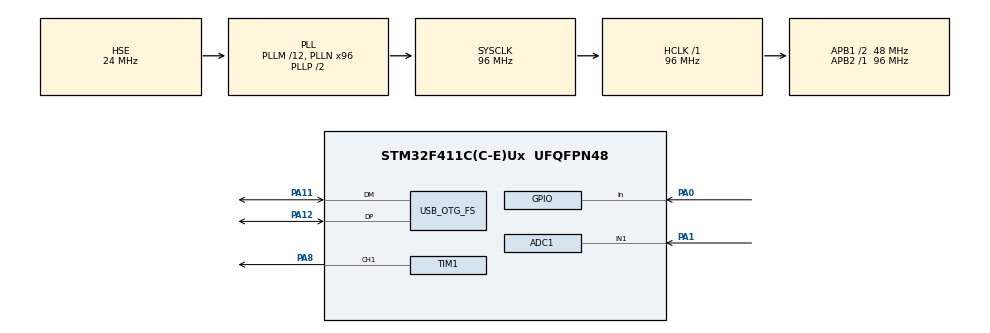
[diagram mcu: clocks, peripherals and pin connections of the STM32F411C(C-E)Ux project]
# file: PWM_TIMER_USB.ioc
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ADC1.Channel-0\#ChannelRegularConversion=ADC_CHANNEL_1
ADC1.NbrOfConversionFlag=1
ADC1.Rank-0\#ChannelRegularConversion=1
ADC1.SamplingTime-0\#ChannelRegularConversion=ADC_SAMPLETIME_3CYCLES
ADC1.master=1
Mcu.Family=STM32F4
Mcu.Name=STM32F411C(C-E)Ux
Mcu.Package=UFQFPN48
NVIC.ADC_IRQn=true\:0\:0\:false\:false\:true\:true\:true\:true
NVIC.OTG_FS_IRQn=true\:0\:0\:false\:false\:true\:false\:true\:true
NVIC.PriorityGroup=NVIC_PRIORITYGROUP_4
PA0-WKUP.GPIO_PuPd=GPIO_PULLUP
PA0-WKUP.Signal=GPIO_Input
PA1.Signal=ADCx_IN1
PA11.Mode=Device_Only
PA11.Signal=USB_OTG_FS_DM
PA12.Mode=Device_Only
PA12.Signal=USB_OTG_FS_DP
PA13.Mode=Serial_Wire
PA13.Signal=SYS_JTMS-SWDIO
PA14.Mode=Serial_Wire
PA14.Signal=SYS_JTCK-SWCLK
PA8.GPIO_PuPd=GPIO_NOPULL
PA8.Signal=S_TIM1_CH1
PH0\ -\ OSC_IN.Mode=HSE-External-Oscillator
PH0\ -\ OSC_IN.Signal=RCC_OSC_IN
PH1\ -\ OSC_OUT.Mode=HSE-External-Oscillator
PH1\ -\ OSC_OUT.Signal=RCC_OSC_OUT
ProjectManager.HeapSize=0x200
ProjectManager.StackSize=0x400
ProjectManager.TargetToolchain=STM32CubeIDE
RCC.48MHZClocksFreq_Value=48000000
RCC.AHBFreq_Value=96000000
RCC.APB1CLKDivider=RCC_HCLK_DIV2
RCC.APB1Freq_Value=48000000
RCC.APB1TimFreq_Value=96000000
RCC.APB2Freq_Value=96000000
RCC.APB2TimFreq_Value=96000000
RCC.CortexFreq_Value=96000000
RCC.HCLKFreq_Value=96000000
RCC.HSE_VALUE=24000000
RCC.HSI_VALUE=16000000
RCC.LSE_VALUE=32768
RCC.PLLM=12
RCC.PLLN=96
RCC.SYSCLKFreq_VALUE=96000000
RCC.SYSCLKSource=RCC_SYSCLKSOURCE_PLLCLK
RCC.VCOOutputFreq_Value=192000000
SH.ADCx_IN1.0=ADC1_IN1,IN1
SH.S_TIM1_CH1.0=TIM1_CH1,PWM Generation1 CH1
TIM1.AutoReloadPreload=TIM_AUTORELOAD_PRELOAD_DISABLE
TIM1.Channel-PWM\ Generation1\ CH1=TIM_CHANNEL_1
TIM1.Period=100-1
TIM1.Prescaler=960
TIM1.RepetitionCounter=1-1
USB_DEVICE.CLASS_NAME_FS=CDC
USB_DEVICE.VirtualMode=Cdc
USB_DEVICE.VirtualModeFS=Cdc_FS
USB_OTG_FS.VirtualMode=Device_Only
VP_TIM1_VS_ClockSourceINT.Mode=Internal
VP_USB_DEVICE_VS_USB_DEVICE_CDC_FS.Mode=CDC_FS
board=custom

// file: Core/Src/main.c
/* USER CODE BEGIN Header */
/**
 ******************************************************************************
 * @file           : main.c
 * @brief          : Main program body
 ******************************************************************************
 * @attention
 *
 * Copyright (c) 2023 STMicroelectronics.
 * All rights reserved.
 *
 * This software is licensed under terms that can be found in the LICENSE file
 * in the root directory of this software component.
 * If no LICENSE file comes with this software, it is provided AS-IS.
 *
 ******************************************************************************
 */
/* USER CODE END Header */
#include "main.h"
#include "usb_device.h"

ADC_HandleTypeDef hadc1;

TIM_HandleTypeDef htim1;

/* USER CODE BEGIN PV */
uint16_t adc_valor, DUTY = 0;
char buffer[2];
GPIO_PinState pinState;
int flag = 0;
/* USER CODE END PV */

void SystemClock_Config(void);
static void MX_GPIO_Init(void);
static void MX_ADC1_Init(void);
static void MX_TIM1_Init(void);
/* USER CODE BEGIN PFP */
extern uint8_t CDC_Transmit_FS(uint8_t *Buf, uint16_t Len);
/* USER CODE END PFP */

int main(void)
{

  /* MCU Configuration--------------------------------------------------------*/

  /* Reset of all peripherals, Initializes the Flash interface and the Systick. */
  HAL_Init();

  /* Configure the system clock */
  SystemClock_Config();

  /* Initialize all configured peripherals */
  MX_GPIO_Init();
  MX_ADC1_Init();
  MX_TIM1_Init();
  MX_USB_DEVICE_Init();
  /* USER CODE BEGIN 2 */

	//HAL_ADC_Start_IT(&hadc1);
	HAL_TIM_PWM_Start(&htim1, TIM_CHANNEL_1);

	TIM1->CCR1 = 50;

  /* USER CODE END 2 */

  /* Infinite loop */
  /* USER CODE BEGIN WHILE */
	while (1) {

/*		HAL_ADC_Start_IT(&hadc1);
		TIM1->CCR1 = DUTY;*/

/*		pinState = HAL_GPIO_ReadPin(GPIOA, GPIO_PIN_0);
		if (pinState == GPIO_PIN_SET) {
			DUTY = 25;
		}
		else {
			DUTY = 75;
		}
		TIM1->CCR1 = DUTY;*/

		pinState = HAL_GPIO_ReadPin(GPIOA, GPIO_PIN_8);
		sprintf(buffer, "%d\n", pinState);
		CDC_Transmit_FS(buffer, sizeof(buffer));

		//HAL_Delay(100);

    /* USER CODE END WHILE */

	}
}

void SystemClock_Config(void)
{
  RCC_OscInitTypeDef RCC_OscInitStruct = {0};
  RCC_ClkInitTypeDef RCC_ClkInitStruct = {0};

  /** Configure the main internal regulator output voltage
  */
  __HAL_RCC_PWR_CLK_ENABLE();
  __HAL_PWR_VOLTAGESCALING_CONFIG(PWR_REGULATOR_VOLTAGE_SCALE1);

  /** Initializes the RCC Oscillators according to the specified parameters
  * in the RCC_OscInitTypeDef structure.
  */
  RCC_OscInitStruct.OscillatorType = RCC_OSCILLATORTYPE_HSE;
  RCC_OscInitStruct.HSEState = RCC_HSE_ON;
  RCC_OscInitStruct.PLL.PLLState = RCC_PLL_ON;
  RCC_OscInitStruct.PLL.PLLSource = RCC_PLLSOURCE_HSE;
  RCC_OscInitStruct.PLL.PLLM = 12;
  RCC_OscInitStruct.PLL.PLLN = 96;
  RCC_OscInitStruct.PLL.PLLP = RCC_PLLP_DIV2;
  RCC_OscInitStruct.PLL.PLLQ = 4;
  if (HAL_RCC_OscConfig(&RCC_OscInitStruct) != HAL_OK)
  {
    Error_Handler();
  }

  /** Initializes the CPU, AHB and APB buses clocks
  */
  RCC_ClkInitStruct.ClockType = RCC_CLOCKTYPE_HCLK|RCC_CLOCKTYPE_SYSCLK
                              |RCC_CLOCKTYPE_PCLK1|RCC_CLOCKTYPE_PCLK2;
  RCC_ClkInitStruct.SYSCLKSource = RCC_SYSCLKSOURCE_PLLCLK;
  RCC_ClkInitStruct.AHBCLKDivider = RCC_SYSCLK_DIV1;
  RCC_ClkInitStruct.APB1CLKDivider = RCC_HCLK_DIV2;
  RCC_ClkInitStruct.APB2CLKDivider = RCC_HCLK_DIV1;

  if (HAL_RCC_ClockConfig(&RCC_ClkInitStruct, FLASH_LATENCY_3) != HAL_OK)
  {
    Error_Handler();
  }
}

static void MX_ADC1_Init(void)
{

  ADC_ChannelConfTypeDef sConfig = {0};

  /** Configure the global features of the ADC (Clock, Resolution, Data Alignment and number of conversion)
  */
  hadc1.Instance = ADC1;
  hadc1.Init.ClockPrescaler = ADC_CLOCK_SYNC_PCLK_DIV4;
  hadc1.Init.Resolution = ADC_RESOLUTION_12B;
  hadc1.Init.ScanConvMode = DISABLE;
  hadc1.Init.ContinuousConvMode = DISABLE;
  hadc1.Init.DiscontinuousConvMode = DISABLE;
  hadc1.Init.ExternalTrigConvEdge = ADC_EXTERNALTRIGCONVEDGE_NONE;
  hadc1.Init.ExternalTrigConv = ADC_SOFTWARE_START;
  hadc1.Init.DataAlign = ADC_DATAALIGN_RIGHT;
  hadc1.Init.NbrOfConversion = 1;
  hadc1.Init.DMAContinuousRequests = DISABLE;
  hadc1.Init.EOCSelection = ADC_EOC_SINGLE_CONV;
  if (HAL_ADC_Init(&hadc1) != HAL_OK)
  {
    Error_Handler();
  }

  /** Configure for the selected ADC regular channel its corresponding rank in the sequencer and its sample time.
  */
  sConfig.Channel = ADC_CHANNEL_1;
  sConfig.Rank = 1;
  sConfig.SamplingTime = ADC_SAMPLETIME_3CYCLES;
  if (HAL_ADC_ConfigChannel(&hadc1, &sConfig) != HAL_OK)
  {
    Error_Handler();
  }

}

static void MX_TIM1_Init(void)
{

  TIM_ClockConfigTypeDef sClockSourceConfig = {0};
  TIM_MasterConfigTypeDef sMasterConfig = {0};
  TIM_OC_InitTypeDef sConfigOC = {0};
  TIM_BreakDeadTimeConfigTypeDef sBreakDeadTimeConfig = {0};

  htim1.Instance = TIM1;
  htim1.Init.Prescaler = 960;
  htim1.Init.CounterMode = TIM_COUNTERMODE_UP;
  htim1.Init.Period = 100-1;
  htim1.Init.ClockDivision = TIM_CLOCKDIVISION_DIV1;
  htim1.Init.RepetitionCounter = 1-1;
  htim1.Init.AutoReloadPreload = TIM_AUTORELOAD_PRELOAD_DISABLE;
  if (HAL_TIM_Base_Init(&htim1) != HAL_OK)
  {
    Error_Handler();
  }
  sClockSourceConfig.ClockSource = TIM_CLOCKSOURCE_INTERNAL;
  if (HAL_TIM_ConfigClockSource(&htim1, &sClockSourceConfig) != HAL_OK)
  {
    Error_Handler();
  }
  if (HAL_TIM_PWM_Init(&htim1) != HAL_OK)
  {
    Error_Handler();
  }
  sMasterConfig.MasterOutputTrigger = TIM_TRGO_RESET;
  sMasterConfig.MasterSlaveMode = TIM_MASTERSLAVEMODE_DISABLE;
  if (HAL_TIMEx_MasterConfigSynchronization(&htim1, &sMasterConfig) != HAL_OK)
  {
    Error_Handler();
  }
  sConfigOC.OCMode = TIM_OCMODE_PWM1;
  sConfigOC.Pulse = 0;
  sConfigOC.OCPolarity = TIM_OCPOLARITY_HIGH;
  sConfigOC.OCNPolarity = TIM_OCNPOLARITY_HIGH;
  sConfigOC.OCFastMode = TIM_OCFAST_DISABLE;
  sConfigOC.OCIdleState = TIM_OCIDLESTATE_RESET;
  sConfigOC.OCNIdleState = TIM_OCNIDLESTATE_RESET;
  if (HAL_TIM_PWM_ConfigChannel(&htim1, &sConfigOC, TIM_CHANNEL_1) != HAL_OK)
  {
    Error_Handler();
  }
  sBreakDeadTimeConfig.OffStateRunMode = TIM_OSSR_DISABLE;
  sBreakDeadTimeConfig.OffStateIDLEMode = TIM_OSSI_DISABLE;
  sBreakDeadTimeConfig.LockLevel = TIM_LOCKLEVEL_OFF;
  sBreakDeadTimeConfig.DeadTime = 0;
  sBreakDeadTimeConfig.BreakState = TIM_BREAK_DISABLE;
  sBreakDeadTimeConfig.BreakPolarity = TIM_BREAKPOLARITY_HIGH;
  sBreakDeadTimeConfig.AutomaticOutput = TIM_AUTOMATICOUTPUT_DISABLE;
  if (HAL_TIMEx_ConfigBreakDeadTime(&htim1, &sBreakDeadTimeConfig) != HAL_OK)
  {
    Error_Handler();
  }
  HAL_TIM_MspPostInit(&htim1);

}

static void MX_GPIO_Init(void)
{
  GPIO_InitTypeDef GPIO_InitStruct = {0};

  /* GPIO Ports Clock Enable */
  __HAL_RCC_GPIOH_CLK_ENABLE();
  __HAL_RCC_GPIOA_CLK_ENABLE();

  /*Configure GPIO pin : PA0 */
  GPIO_InitStruct.Pin = GPIO_PIN_0;
  GPIO_InitStruct.Mode = GPIO_MODE_INPUT;
  GPIO_InitStruct.Pull = GPIO_PULLUP;
  HAL_GPIO_Init(GPIOA, &GPIO_InitStruct);

}

/* USER CODE BEGIN 4 */
void HAL_ADC_ConvCpltCallback(ADC_HandleTypeDef *hadc1) {
	/*
	 adc_valor = HAL_ADC_GetValue(hadc1);
	 HAL_ADC_Stop_IT(hadc1);
	 DUTY = ((80 * adc_valor) / 4096) + 10;

	 */

/*	adc_valor = HAL_ADC_GetValue(hadc1);
	HAL_ADC_Stop_IT(hadc1);

	DUTY = ((adc_valor * 100) / 4096);*/

}

void HAL_GPIO_EXTI_Callback(uint16_t GPIO_Pin) {
	if (GPIO_Pin == GPIO_PIN_0) {
		flag = 1;
	}
}

/* USER CODE END 4 */

void Error_Handler(void)
{
	__disable_irq();
	while (1) {
	}
}
